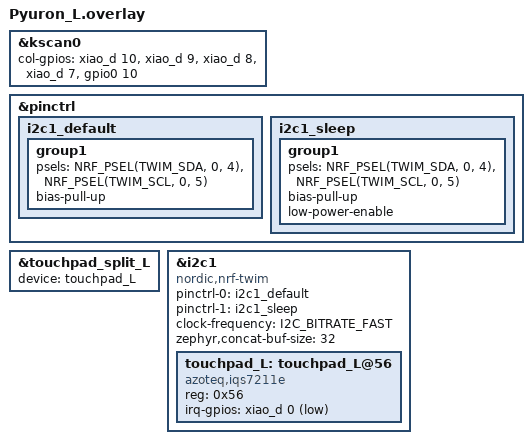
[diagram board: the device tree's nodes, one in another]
#include <input/processors.dtsi>
#include <dt-bindings/zmk/input_transform.h>
#include <zephyr/dt-bindings/input/input-event-codes.h>
#include <dt-bindings/zmk/keys.h>
#include "Pyuron.dtsi"

&kscan0 {
        col-gpios
            = <&xiao_d 10 GPIO_ACTIVE_HIGH>
            , <&xiao_d 9 GPIO_ACTIVE_HIGH> 
            , <&xiao_d 8 GPIO_ACTIVE_HIGH> 
            , <&xiao_d 7 GPIO_ACTIVE_HIGH> 
            , <&gpio0 10 GPIO_ACTIVE_HIGH>
            ;
};

&pinctrl {
	i2c1_default: i2c1_default {
		group1 {
			psels = <NRF_PSEL(TWIM_SDA, 0, 4)>,
				    <NRF_PSEL(TWIM_SCL, 0, 5)>;
            bias-pull-up;
		};
	};

	i2c1_sleep: i2c1_sleep {
		group1 {
			psels = <NRF_PSEL(TWIM_SDA, 0, 4)>,
				    <NRF_PSEL(TWIM_SCL, 0, 5)>;
            bias-pull-up;
			low-power-enable;
		};
	};
};

&touchpad_split_L {
    device = <&touchpad_L>;
};

&i2c1 {
    status = "okay";
    compatible = "nordic,nrf-twim";
    pinctrl-0 = <&i2c1_default>;
    pinctrl-1 = <&i2c1_sleep>;
    pinctrl-names = "default", "sleep";
    clock-frequency = <I2C_BITRATE_FAST>;
    zephyr,concat-buf-size = <32>;

    touchpad_L: touchpad_L@56 {
        status = "okay";
        compatible = "azoteq,iqs7211e";
        reg = <0x56>;
        irq-gpios = <&xiao_d 0 (GPIO_ACTIVE_LOW | GPIO_PULL_UP)>;
       // power-gpios = <&gpio0 9 GPIO_ACTIVE_HIGH>;
    };
};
